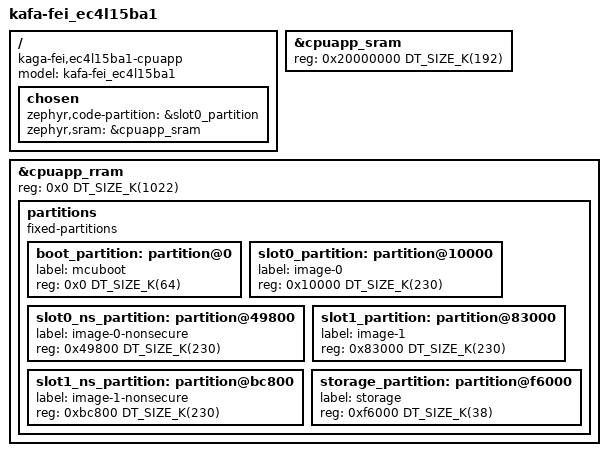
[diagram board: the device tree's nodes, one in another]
/*
 * Copyright (c) 2024 Nordic Semiconductor ASA
 * Copyright (c) 2025 KAGA FEI Co., Ltd.
 *
 * SPDX-License-Identifier: Apache-2.0
 */

/dts-v1/;

#include <nordic/nrf54l10_cpuapp.dtsi>
#include "ec4l15ba1-pinctrl.dtsi"

/ {
	model = "kafa-fei_ec4l15ba1";
	compatible = "kaga-fei,ec4l15ba1-cpuapp";

	chosen {
		zephyr,code-partition = &slot0_partition;
		zephyr,sram = &cpuapp_sram;
	};
};

/* FLPR not supported yet, give all SRAM and RRAM to the APP core */
&cpuapp_sram {
	reg = <0x20000000 DT_SIZE_K(192)>;
	ranges = <0x0 0x20000000 DT_SIZE_K(192)>;
};

&cpuapp_rram {
	reg = <0x0 DT_SIZE_K(1022)>;
};

/* These partition sizes assume no FLPR area in RRAM */
&cpuapp_rram {
	partitions {
		compatible = "fixed-partitions";
		#address-cells = <1>;
		#size-cells = <1>;
		boot_partition: partition@0 {
			label = "mcuboot";
			reg = <0x0 DT_SIZE_K(64)>;
		};
		slot0_partition: partition@10000 {
			label = "image-0";
			reg = <0x10000 DT_SIZE_K(230)>;
		};
		slot0_ns_partition: partition@49800 {
			label = "image-0-nonsecure";
			reg = <0x49800 DT_SIZE_K(230)>;
		};
		slot1_partition: partition@83000 {
			label = "image-1";
			reg = <0x83000 DT_SIZE_K(230)>;
		};
		slot1_ns_partition: partition@bc800 {
			label = "image-1-nonsecure";
			reg = <0xbc800 DT_SIZE_K(230)>;
		};
		storage_partition: partition@f6000 {
			label = "storage";
			reg = <0xf6000 DT_SIZE_K(38)>;
		};
	};
};
